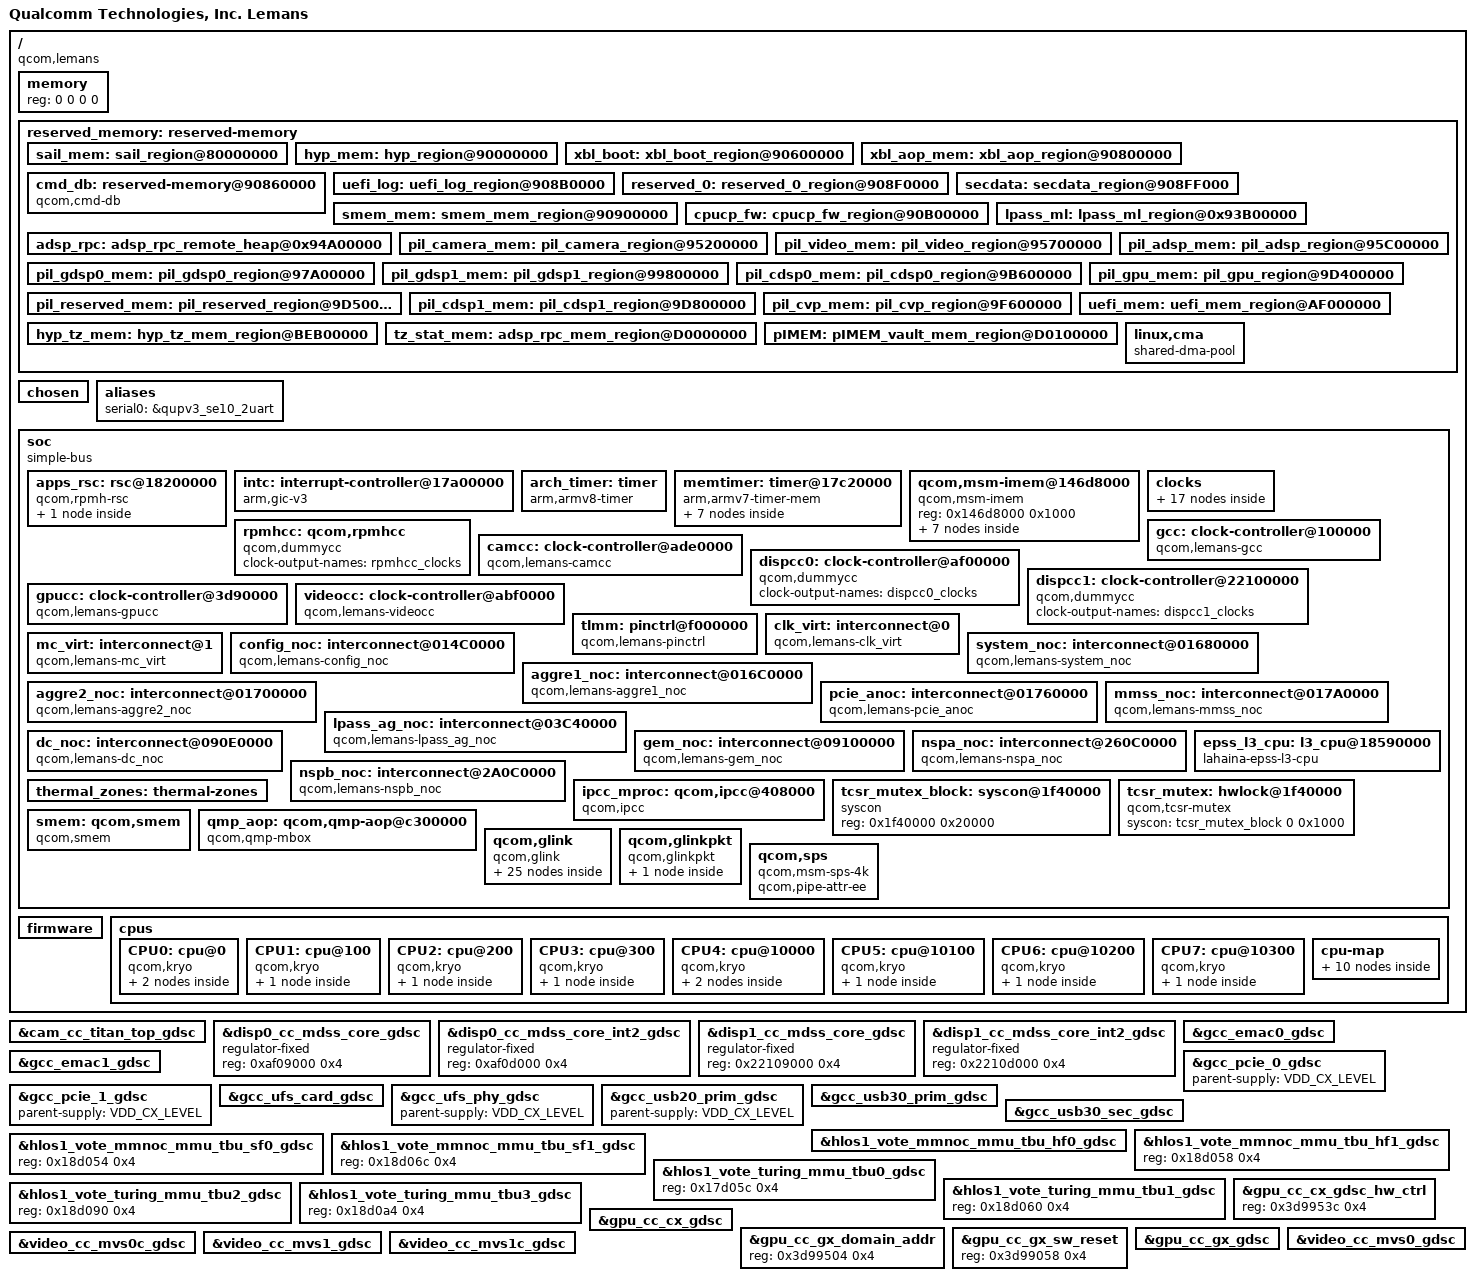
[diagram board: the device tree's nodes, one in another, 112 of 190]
#include <dt-bindings/clock/qcom,rpmh.h>
#include <dt-bindings/clock/qcom,camcc-lemans.h>
#include <dt-bindings/clock/qcom,dispcc-lemans.h>
#include <dt-bindings/clock/qcom,gcc-lemans.h>
#include <dt-bindings/clock/qcom,gpucc-lemans.h>
#include <dt-bindings/clock/qcom,videocc-lemans.h>
#include <dt-bindings/interconnect/qcom,epss-l3.h>
#include <dt-bindings/interconnect/qcom,lemans.h>
#include <dt-bindings/interrupt-controller/arm-gic.h>
#include <dt-bindings/soc/qcom,rpmh-rsc.h>
#include <dt-bindings/soc/qcom,ipcc.h>

/ {
	model = "Qualcomm Technologies, Inc. Lemans";
	compatible = "qcom,lemans";
	qcom,msm-id = <532 0x10000>, <534 0x10000>;
	interrupt-parent = <&intc>;

	#address-cells = <2>;
	#size-cells = <2>;
	memory { device_type = "memory"; reg = <0 0 0 0>; };

	reserved_memory: reserved-memory { };

	chosen: chosen { };

	aliases {
		serial0 = &qupv3_se10_2uart;
	 };

	soc: soc { };

	firmware: firmware { };

	cpus {
		#address-cells = <2>;
		#size-cells = <0>;

		CPU0: cpu@0 {
			device_type = "cpu";
			compatible = "qcom,kryo";
			reg = <0x0 0x0>;
			enable-method = "spin-table";
			cpu-release-addr = <0x0 0xC0000000>;
			cache-size = <0x20000>;
			next-level-cache = <&L2_0>;
			L2_0: l2-cache {
			      compatible = "arm,arch-cache";
			      cache-level = <2>;
			      cache-size = <0x80000>;
			      next-level-cache = <&L3_0>;

				L3_0: l3-cache {
				      compatible = "arm,arch-cache";
				      cache-level = <3>;
				      cache-size = <0x200000>;
				};
			};
		};

		CPU1: cpu@100 {
			device_type = "cpu";
			compatible = "qcom,kryo";
			reg = <0x0 0x100>;
			enable-method = "spin-table";
			cpu-release-addr = <0x0 0xC0000000>;
			cache-size = <0x20000>;
			next-level-cache = <&L2_1>;
			L2_1: l2-cache {
			      compatible = "arm,arch-cache";
			      cache-level = <2>;
			      cache-size = <0x80000>;
			      next-level-cache = <&L3_0>;
			};
		};

		CPU2: cpu@200 {
			device_type = "cpu";
			compatible = "qcom,kryo";
			reg = <0x0 0x200>;
			enable-method = "spin-table";
			cpu-release-addr = <0x0 0xC0000000>;
			cache-size = <0x20000>;
			next-level-cache = <&L2_2>;
			L2_2: l2-cache {
			      compatible = "arm,arch-cache";
			      cache-level = <2>;
			      cache-size = <0x80000>;
			      next-level-cache = <&L3_0>;
			};
		};

		CPU3: cpu@300 {
			device_type = "cpu";
			compatible = "qcom,kryo";
			reg = <0x0 0x300>;
			enable-method = "spin-table";
			cpu-release-addr = <0x0 0xC0000000>;
			cache-size = <0x20000>;
			next-level-cache = <&L2_3>;
			L2_3: l2-cache {
			      compatible = "arm,arch-cache";
			      cache-level = <2>;
			      cache-size = <0x80000>;
			      next-level-cache = <&L3_0>;
			};
		};

		CPU4: cpu@10000 {
			device_type = "cpu";
			compatible = "qcom,kryo";
			reg = <0x0 0x10000>;
			enable-method = "spin-table";
			cache-size = <0x20000>;
			cpu-release-addr = <0x0 0xC0000000>;
			next-level-cache = <&L2_4>;
			L2_4: l2-cache {
			      compatible = "arm,arch-cache";
			      cache-level = <2>;
			      cache-size = <0x80000>;
			      next-level-cache = <&L3_1>;
				L3_1: l3-cache {
				      compatible = "arm,arch-cache";
				      cache-level = <3>;
				      cache-size = <0x200000>;
				};

			};
		};

		CPU5: cpu@10100 {
			device_type = "cpu";
			compatible = "qcom,kryo";
			reg = <0x0 0x10100>;
			enable-method = "spin-table";
			cpu-release-addr = <0x0 0xC0000000>;
			cache-size = <0x20000>;
			next-level-cache = <&L2_5>;
			L2_5: l2-cache {
			      compatible = "arm,arch-cache";
			      cache-level = <2>;
			      cache-size = <0x80000>;
			      next-level-cache = <&L3_1>;
			};
		};

		CPU6: cpu@10200 {
			device_type = "cpu";
			compatible = "qcom,kryo";
			reg = <0x0 0x10200>;
			enable-method = "spin-table";
			cpu-release-addr = <0x0 0xC0000000>;
			cache-size = <0x20000>;
			next-level-cache = <&L2_6>;
			L2_6: l2-cache {
			      compatible = "arm,arch-cache";
			      cache-level = <2>;
			      cache-size = <0x80000>;
			      next-level-cache = <&L3_1>;
			};
		};

		CPU7: cpu@10300 {
			device_type = "cpu";
			compatible = "qcom,kryo";
			reg = <0x0 0x10300>;
			enable-method = "spin-table";
			cpu-release-addr = <0x0 0xC0000000>;
			cache-size = <0x20000>;
			next-level-cache = <&L2_7>;
			L2_7: l2-cache {
			      compatible = "arm,arch-cache";
			      cache-level = <2>;
			      cache-size = <0x80000>;
			      next-level-cache = <&L3_1>;
			};
		};

		cpu-map {
			cluster0 {
				core0 {
					cpu = <&CPU0>;
				};

				core1 {
					cpu = <&CPU1>;
				};

				core2 {
					cpu = <&CPU2>;
				};

				core3 {
					cpu = <&CPU3>;
				};
			};

			cluster1 {
				core0 {
					cpu = <&CPU4>;
				};

				core1 {
					cpu = <&CPU5>;
				};

				core2 {
					cpu = <&CPU6>;
				};

				core3 {
					cpu = <&CPU7>;
				};
			};
		};
	};
};

&reserved_memory {
	#address-cells = <2>;
	#size-cells = <2>;
	ranges;

	sail_mem: sail_region@80000000 {
		no-map;
		reg = <0x0 0x80000000 0x0 0x10000000>;
	};

	hyp_mem: hyp_region@90000000 {
		no-map;
		reg = <0x0 0x90000000 0x0 0x600000>;
	};

	xbl_boot: xbl_boot_region@90600000 {
		no-map;
		reg = <0x0 0x90600000 0x0 0x200000>;
	};

	xbl_aop_mem: xbl_aop_region@90800000 {
		no-map;
		reg = <0x0 0x90800000 0x0 0x60000>;
	};

	cmd_db: reserved-memory@90860000 {
		compatible = "qcom,cmd-db";
		no-map;
		reg = <0x0 0x90860000 0x0 0x20000>;
	};

	uefi_log: uefi_log_region@908B0000 {
		no-map;
		reg = <0x0 0x908B0000 0x0 0x10000>;
	};

	reserved_0: reserved_0_region@908F0000 {
		no-map;
		reg = <0x0 0x908F0000 0x0 0xF000>;
	};

	secdata: secdata_region@908FF000 {
		no-map;
		reg = <0x0 0x908FF000 0x0 0x1000>;
	};

	smem_mem: smem_mem_region@90900000 {
		no-map;
		reg = <0x0 0x90900000 0x0 0x200000>;
	};

	cpucp_fw: cpucp_fw_region@90B00000 {
		no-map;
		reg = <0x0 0x90B00000 0x0 0x100000>;
	};

	lpass_ml: lpass_ml_region@0x93B00000 {
		no-map;
		reg = <0x0 0x93B00000 0x0 0xF00000>;
	};

	adsp_rpc: adsp_rpc_remote_heap@0x94A00000 {
		no-map;
		reg = <0x0 0x94A00000 0x0 0x800000>;
	};

	pil_camera_mem: pil_camera_region@95200000 {
		no-map;
		reg = <0x0 0x95200000 0x0 0x500000>;
	};

	pil_video_mem: pil_video_region@95700000 {
		no-map;
		reg = <0x0 0x95700000 0x0 0x500000>;
	};

	pil_adsp_mem: pil_adsp_region@95C00000 {
		no-map;
		reg = <0x0 0x95C00000 0x0 0x1E00000>;
	};

	pil_gdsp0_mem: pil_gdsp0_region@97A00000 {
		no-map;
		reg = <0x0 0x97A00000 0x0 0x1e00000>;
	};

	pil_gdsp1_mem: pil_gdsp1_region@99800000 {
		no-map;
		reg = <0x0 0x99800000 0x0 0x1e00000>;
	};

	pil_cdsp0_mem: pil_cdsp0_region@9B600000 {
		no-map;
		reg = <0x0 0x9B600000 0x0 0x1e00000>;
	};

	pil_gpu_mem: pil_gpu_region@9D400000 {
		no-map;
		reg = <0x0 0x9D400000 0x0 0x2000>;
	};

	pil_reserved_mem: pil_reserved_region@9D500000 {
		no-map;
		reg = <0x0 0x9D500000 0x0 0x300000>;
	};

	pil_cdsp1_mem: pil_cdsp1_region@9D800000 {
		no-map;
		reg = <0x0 0x9D800000 0x0 0x1E00000>;
	};

	pil_cvp_mem: pil_cvp_region@9F600000 {
		no-map;
		reg = <0x0 0x9F600000 0x0 0x700000>;
	};

	uefi_mem: uefi_mem_region@AF000000 {
		no-map;
		reg = <0x0 0xAF000000 0x0 0x1000000>;
	};

	hyp_tz_mem: hyp_tz_mem_region@BEB00000 {
		no-map;
		reg = <0x0 0xBEB00000 0x0 0x11500000>;
	};

	tz_stat_mem: adsp_rpc_mem_region@D0000000 {
		no-map;
		reg = <0x0 0xD0000000 0x0 0x100000>;
	};

	pIMEM: pIMEM_vault_mem_region@D0100000 {
		no-map;
		reg = <0x0 0xD0100000 0x0 0x5000000>;
	};

	  /* global autoconfigured region for contiguous allocations */
	linux,cma {
		compatible = "shared-dma-pool";
		alloc-ranges = <0x0 0x00000000 0x0 0xdfffffff>;
		reusable;
		alignment = <0x0 0x400000>;
		size = <0x0 0x2000000>;
		linux,cma-default;
	};
};

&soc {
	#address-cells = <1>;
	#size-cells = <1>;
	ranges = <0 0 0 0xffffffff>;
	compatible = "simple-bus";

	apps_rsc: rsc@18200000 {
		label = "apps_rsc";
		compatible = "qcom,rpmh-rsc";
		reg = <0x18200000 0x10000>,
		      <0x18210000 0x10000>,
		      <0x18220000 0x10000>;
		reg-names = "drv-0", "drv-1", "drv-2";
		interrupts = <GIC_SPI 3 IRQ_TYPE_LEVEL_HIGH>,
			     <GIC_SPI 4 IRQ_TYPE_LEVEL_HIGH>,
			     <GIC_SPI 5 IRQ_TYPE_LEVEL_HIGH>;
		qcom,tcs-offset = <0xd00>;
		qcom,drv-id = <2>;
		qcom,tcs-config = <ACTIVE_TCS  2>,
				  <SLEEP_TCS   3>,
				  <WAKE_TCS    3>,
				  <CONTROL_TCS 0>;

		apps_bcm_voter: bcm_voter {
			compatible = "qcom,bcm-voter";
		};
	};

	intc: interrupt-controller@17a00000 {
		compatible = "arm,gic-v3";
		#interrupt-cells = <3>;
		interrupt-controller;
		#redistributor-regions = <1>;
		redistributor-stride = <0x0 0x20000>;
		reg = <0x17a00000 0x10000>,     /* GICD */
		      <0x17a60000 0x100000>;    /* GICR * 8 */
		interrupts = <GIC_PPI 9 IRQ_TYPE_LEVEL_HIGH>;
	};

	arch_timer: timer {
		compatible = "arm,armv8-timer";
		interrupts = <GIC_PPI 13 (GIC_CPU_MASK_SIMPLE(8) | IRQ_TYPE_LEVEL_LOW)>,
			     <GIC_PPI 14 (GIC_CPU_MASK_SIMPLE(8) | IRQ_TYPE_LEVEL_LOW)>,
			     <GIC_PPI 11 (GIC_CPU_MASK_SIMPLE(8) | IRQ_TYPE_LEVEL_LOW)>,
			     <GIC_PPI 12 (GIC_CPU_MASK_SIMPLE(8) | IRQ_TYPE_LEVEL_LOW)>;
		clock-frequency = <19200000>;
	};

	memtimer: timer@17c20000 {
		#address-cells = <1>;
		#size-cells = <1>;
		ranges;
		compatible = "arm,armv7-timer-mem";
		reg = <0x17c20000 0x1000>;
		clock-frequency = <19200000>;

		frame@17c21000 {
			frame-number = <0>;
			interrupts = <GIC_SPI 8 IRQ_TYPE_LEVEL_HIGH>,
				     <GIC_SPI 6 IRQ_TYPE_LEVEL_HIGH>;
			reg = <0x17c21000 0x1000>,
			      <0x17c22000 0x1000>;
		};

		frame@17c23000 {
			frame-number = <1>;
			interrupts = <GIC_SPI 9 IRQ_TYPE_LEVEL_HIGH>;
			reg = <0x17c23000 0x1000>;
			status = "disabled";
		};

		frame@17c25000 {
			frame-number = <2>;
			interrupts = <GIC_SPI 10 IRQ_TYPE_LEVEL_HIGH>;
			reg = <0x17c25000 0x1000>;
			status = "disabled";
		};

		frame@17c27000 {
			frame-number = <3>;
			interrupts = <GIC_SPI 11 IRQ_TYPE_LEVEL_HIGH>;
			reg = <0x17c27000 0x1000>;
			status = "disabled";
		};

		frame@17c29000 {
			frame-number = <4>;
			interrupts = <GIC_SPI 12 IRQ_TYPE_LEVEL_HIGH>;
			reg = <0x17c29000 0x1000>;
			status = "disabled";
		};

		frame@17c2b000 {
			frame-number = <5>;
			interrupts = <GIC_SPI 13 IRQ_TYPE_LEVEL_HIGH>;
			reg = <0x17c2b000 0x1000>;
			status = "disabled";
		};

		frame@17c2d000 {
			frame-number = <6>;
			interrupts = <GIC_SPI 14 IRQ_TYPE_LEVEL_HIGH>;
			reg = <0x17c2d000 0x1000>;
			status = "disabled";
		};
	};

	qcom,msm-imem@146d8000 {
		compatible = "qcom,msm-imem";
		reg = <0x146d8000 0x1000>;
		ranges = <0x0 0x146d8000 0x1000>;
		#address-cells = <1>;
		#size-cells = <1>;

		mem_dump_table@10 {
			compatible = "qcom,msm-imem-mem_dump_table";
			reg = <0x10 0x8>;
		};

		restart_reason@65c {
			compatible = "qcom,msm-imem-restart_reason";
			reg = <0x65c 0x4>;
		};

		dload_type@1c {
			compatible = "qcom,msm-imem-dload-type";
			reg = <0x1c 0x4>;
		};

		boot_stats@6b0 {
			compatible = "qcom,msm-imem-boot_stats";
			reg = <0x6b0 0x20>;
		};

		kaslr_offset@6d0 {
			compatible = "qcom,msm-imem-kaslr_offset";
			reg = <0x6d0 0xc>;
		};

		pil@94c {
			compatible = "qcom,msm-imem-pil";
			reg = <0x94c 0xc8>;
		};

		diag_dload@c8 {
			compatible = "qcom,msm-imem-diag-dload";
			reg = <0xc8 0xc8>;
		};
	};

	clocks {
		xo_board: xo_board {
			compatible = "fixed-clock";
			clock-frequency = <38400000>;
			clock-output-names = "xo_board";
			#clock-cells = <0>;
		};

		bi_tcxo: bi_tcxo {
			compatible = "fixed-factor-clock";
			clock-mult = <1>;
			clock-div = <2>;
			clocks = <&xo_board>;
			clock-output-names = "bi_tcxo";
			#clock-cells = <0>;
		};

		bi_tcxo_ao: bi_tcxo_ao {
			compatible = "fixed-factor-clock";
			clock-mult = <1>;
			clock-div = <2>;
			clocks = <&xo_board>;
			clock-output-names = "bi_tcxo_ao";
			#clock-cells = <0>;
		};

		sleep_clk: sleep_clk {
			compatible = "fixed-clock";
			clock-frequency = <32000>;
			clock-output-names = "sleep_clk";
			#clock-cells = <0>;
		};

		pcie_0_pipe_clk: pcie_0_pipe_clk {
			compatible = "fixed-clock";
			clock-frequency = <1000>;
			clock-output-names = "pcie_0_pipe_clk";
			#clock-cells = <0>;
		};

		pcie_1_pipe_clk: pcie_1_pipe_clk {
			compatible = "fixed-clock";
			clock-frequency = <1000>;
			clock-output-names = "pcie_1_pipe_clk";
			#clock-cells = <0>;
		};

		pcie_phy_aux_clk: pcie_phy_aux_clk {
			compatible = "fixed-clock";
			clock-frequency = <1000>;
			clock-output-names = "pcie_phy_aux_clk";
			#clock-cells = <0>;
		};

		rxc0_ref_clk: rxc0_ref_clk {
			compatible = "fixed-clock";
			clock-frequency = <1000>;
			clock-output-names = "rxc0_ref_clk";
			#clock-cells = <0>;
		};

		rxc1_ref_clk: rxc1_ref_clk {
			compatible = "fixed-clock";
			clock-frequency = <1000>;
			clock-output-names = "rxc0_ref_clk";
			#clock-cells = <0>;
		};

		ufs_card_rx_symbol_0_clk: ufs_card_rx_symbol_0_clk {
			compatible = "fixed-clock";
			clock-frequency = <1000>;
			clock-output-names = "ufs_card_rx_symbol_0_clk";
			#clock-cells = <0>;
		};

		ufs_card_rx_symbol_1_clk: ufs_card_rx_symbol_1_clk {
			compatible = "fixed-clock";
			clock-frequency = <1000>;
			clock-output-names = "ufs_card_rx_symbol_1_clk";
			#clock-cells = <0>;
		};

		ufs_card_tx_symbol_0_clk: ufs_card_tx_symbol_0_clk {
			compatible = "fixed-clock";
			clock-frequency = <1000>;
			clock-output-names = "ufs_card_tx_symbol_0_clk";
			#clock-cells = <0>;
		};

		ufs_phy_rx_symbol_0_clk: ufs_phy_rx_symbol_0_clk {
			compatible = "fixed-clock";
			clock-frequency = <1000>;
			clock-output-names = "ufs_phy_rx_symbol_0_clk";
			#clock-cells = <0>;
		};

		ufs_phy_rx_symbol_1_clk: ufs_phy_rx_symbol_1_clk {
			compatible = "fixed-clock";
			clock-frequency = <1000>;
			clock-output-names = "ufs_phy_rx_symbol_1_clk";
			#clock-cells = <0>;
		};

		ufs_phy_tx_symbol_0_clk: ufs_phy_tx_symbol_0_clk {
			compatible = "fixed-clock";
			clock-frequency = <1000>;
			clock-output-names = "ufs_phy_tx_symbol_0_clk";
			#clock-cells = <0>;
		};

		usb3_phy_wrapper_gcc_usb30_prim_pipe_clk: usb3_phy_wrapper_gcc_usb30_prim_pipe_clk {
			compatible = "fixed-clock";
			clock-frequency = <1000>;
			clock-output-names = "usb3_phy_wrapper_gcc_usb30_prim_pipe_clk";
			#clock-cells = <0>;
		};

		usb3_phy_wrapper_gcc_usb30_sec_pipe_clk: usb3_phy_wrapper_gcc_usb30_sec_pipe_clk {
			compatible = "fixed-clock";
			clock-frequency = <1000>;
			clock-output-names = "usb3_phy_wrapper_gcc_usb30_sec_pipe_clk";
			#clock-cells = <0>;
		};
	};

	rpmhcc: qcom,rpmhcc {
		compatible = "qcom,dummycc";
		clock-output-names = "rpmhcc_clocks";
		#clock-cells = <1>;
		#reset-cells = <1>;
	};

	gcc: clock-controller@100000 {
		compatible = "qcom,lemans-gcc", "syscon";
		reg = <0x100000 0xc7018>;
		reg-name = "cc_base";
		vdd_cx-supply = <&VDD_CX_LEVEL>;
		clocks = <&rpmhcc RPMH_CXO_CLK>, <&pcie_0_pipe_clk>, <&pcie_1_pipe_clk>,
			 <&pcie_phy_aux_clk>, <&rxc0_ref_clk>, <&rxc1_ref_clk>, <&sleep_clk>,
			 <&ufs_card_rx_symbol_0_clk>, <&ufs_card_rx_symbol_1_clk>,
			 <&ufs_card_tx_symbol_0_clk>, <&ufs_phy_rx_symbol_0_clk>,
			 <&ufs_phy_rx_symbol_1_clk>, <&ufs_phy_tx_symbol_0_clk>,
			 <&usb3_phy_wrapper_gcc_usb30_prim_pipe_clk>,
			 <&usb3_phy_wrapper_gcc_usb30_sec_pipe_clk>;
		clock-names = "bi_tcxo", "pcie_0_pipe_clk", "pcie_1_pipe_clk",
			      "pcie_phy_aux_clk", "rxc0_ref_clk", "rxc1_ref_clk", "sleep_clk",
			      "ufs_card_rx_symbol_0_clk", "ufs_card_rx_symbol_1_clk",
			      "ufs_card_tx_symbol_0_clk", "ufs_phy_rx_symbol_0_clk",
			      "ufs_phy_rx_symbol_1_clk", "ufs_phy_tx_symbol_0_clk",
			      "usb3_phy_wrapper_gcc_usb30_prim_pipe_clk",
			      "usb3_phy_wrapper_gcc_usb30_sec_pipe_clk";
		#clock-cells = <1>;
		#reset-cells = <1>;
	};

	camcc: clock-controller@ade0000 {
		compatible = "qcom,lemans-camcc", "syscon";
		reg = <0xade0000 0x20000>;
		reg-name = "cc_base";
		vdd_mm-supply = <&VDD_MM_LEVEL>;
		vdd_mxa-supply = <&VDD_MXA_LEVEL>;
		vdd_mxc-supply = <&VDD_MXC_LEVEL>;
		clocks = <&rpmhcc RPMH_CXO_CLK>, <&gcc GCC_CAMERA_AHB_CLK>, <&sleep_clk>;
		clock-names = "bi_tcxo", "iface", "sleep_clk";
		#clock-cells = <1>;
		#reset-cells = <1>;
	};

	dispcc0: clock-controller@af00000 {
		compatible = "qcom,dummycc";
		clock-output-names = "dispcc0_clocks";
		#clock-cells = <1>;
		#reset-cells = <1>;
	};

	dispcc1: clock-controller@22100000 {
		compatible = "qcom,dummycc";
		clock-output-names = "dispcc1_clocks";
		#clock-cells = <1>;
		#reset-cells = <1>;
	};

	gpucc: clock-controller@3d90000 {
		compatible = "qcom,lemans-gpucc", "syscon";
		reg = <0x3d90000 0xa000>;
		reg-name = "cc_base";
		vdd_cx-supply = <&VDD_CX_LEVEL>;
		vdd_mxa-supply = <&VDD_MXA_LEVEL>;
		clocks = <&rpmhcc RPMH_CXO_CLK>, <&gcc GCC_GPU_CFG_AHB_CLK>,
			 <&gcc GCC_GPU_GPLL0_CLK_SRC>, <&gcc GCC_GPU_GPLL0_DIV_CLK_SRC>;
		clock-names = "bi_tcxo", "iface", "gpll0_out_main", "gpll0_out_main_div";
		#clock-cells = <1>;
		#reset-cells = <1>;
	};

	videocc: clock-controller@abf0000 {
		compatible = "qcom,lemans-videocc", "syscon";
		reg = <0xabf0000 0x10000>;
		reg-name = "cc_base";
		vdd_mm-supply = <&VDD_MM_LEVEL>;
		vdd_mx-supply = <&VDD_MXA_LEVEL>;
		clocks = <&rpmhcc RPMH_CXO_CLK>, <&gcc GCC_VIDEO_AHB_CLK>, <&sleep_clk>;
		clock-names = "bi_tcxo", "iface", "sleep_clk";
		#clock-cells = <1>;
		#reset-cells = <1>;
	};

	tlmm: pinctrl@f000000 {
		compatible = "qcom,lemans-pinctrl";
		reg = <0xf000000 0x1000000>;
		interrupts = <GIC_SPI 208 IRQ_TYPE_LEVEL_HIGH>;
		gpio-controller;
		#gpio-cells = <2>;
		interrupt-controller;
		#interrupt-cells = <2>;
	};

	clk_virt: interconnect@0 {
		compatible = "qcom,lemans-clk_virt";
		#interconnect-cells = <1>;
		qcom,bcm-voter-names = "hlos";
		qcom,bcm-voters = <&apps_bcm_voter>;
	};

	mc_virt: interconnect@1 {
		compatible = "qcom,lemans-mc_virt";
		#interconnect-cells = <1>;
		qcom,bcm-voter-names = "hlos";
		qcom,bcm-voters = <&apps_bcm_voter>;
	};

	config_noc: interconnect@014C0000 {
		compatible = "qcom,lemans-config_noc";
		reg = <0x014C0000 0x13080>;
		#interconnect-cells = <1>;
		qcom,bcm-voter-names = "hlos";
		qcom,bcm-voters = <&apps_bcm_voter>;
	};

	system_noc: interconnect@01680000 {
		compatible = "qcom,lemans-system_noc";
		reg = <0x01680000 0x15080>;
		#interconnect-cells = <1>;
		qcom,bcm-voter-names = "hlos";
		qcom,bcm-voters = <&apps_bcm_voter>;
	};

	aggre1_noc:interconnect@016C0000 {
		compatible = "qcom,lemans-aggre1_noc";
		reg = <0x016C0000 0x18080>;
		#interconnect-cells = <1>;
		qcom,bcm-voter-names = "hlos";
		qcom,bcm-voters = <&apps_bcm_voter>;
	};

	aggre2_noc: interconnect@01700000 {
		compatible = "qcom,lemans-aggre2_noc";
		reg = <0x01700000 0x1B080>;
		#interconnect-cells = <1>;
		qcom,bcm-voter-names = "hlos";
		qcom,bcm-voters = <&apps_bcm_voter>;
	};

	pcie_anoc: interconnect@01760000 {
		compatible = "qcom,lemans-pcie_anoc";
		reg = <0x01760000 0xC080>;
		#interconnect-cells = <1>;
		qcom,bcm-voter-names = "hlos";
		qcom,bcm-voters = <&apps_bcm_voter>;
	};

	mmss_noc: interconnect@017A0000 {
		compatible = "qcom,lemans-mmss_noc";
		reg = <0x017A0000 0x40000>;
		#interconnect-cells = <1>;
		qcom,bcm-voter-names = "hlos";
		qcom,bcm-voters = <&apps_bcm_voter>;
	};

	lpass_ag_noc: interconnect@03C40000 {
		compatible = "qcom,lemans-lpass_ag_noc";
		reg = <0x3C40000 0x17200>;
		#interconnect-cells = <1>;
		qcom,bcm-voter-names = "hlos";
		qcom,bcm-voters = <&apps_bcm_voter>;
	};

	dc_noc: interconnect@090E0000 {
		compatible = "qcom,lemans-dc_noc";
		reg = <0x090E0000 0x5080>;
		#interconnect-cells = <1>;
		qcom,bcm-voter-names = "hlos";
		qcom,bcm-voters = <&apps_bcm_voter>;
	};

	gem_noc: interconnect@09100000 {
		compatible = "qcom,lemans-gem_noc";
		reg = <0x09100000 0xF6080>;
		#interconnect-cells = <1>;
		qcom,bcm-voter-names = "hlos";
		qcom,bcm-voters = <&apps_bcm_voter>;
	};

	nspa_noc: interconnect@260C0000 {
		compatible = "qcom,lemans-nspa_noc";
		reg = <0x260C0000 0x16080>;
		#interconnect-cells = <1>;
		qcom,bcm-voter-names = "hlos";
		qcom,bcm-voters = <&apps_bcm_voter>;
	};

	nspb_noc: interconnect@2A0C0000 {
		compatible = "qcom,lemans-nspb_noc";
		reg = <0x2A0C0000 0x16080>;
		#interconnect-cells = <1>;
		qcom,bcm-voter-names = "hlos";
		qcom,bcm-voters = <&apps_bcm_voter>;
	};

	epss_l3_cpu: l3_cpu@18590000 {
		compatible = "lahaina-epss-l3-cpu";
		#interconnect-cells = <1>;
	};

	thermal_zones: thermal-zones {
	};

	ipcc_mproc: qcom,ipcc@408000 {
		compatible = "qcom,ipcc";
		reg = <0x408000 0x1000>;
		interrupts = <GIC_SPI 229 IRQ_TYPE_LEVEL_HIGH>;
		interrupt-controller;
		#interrupt-cells = <3>;
		#mbox-cells = <2>;
	};

	tcsr_mutex_block: syscon@1f40000 {
		compatible = "syscon";
		reg = <0x1f40000 0x20000>;
	};

	tcsr_mutex: hwlock@1f40000 {
		compatible = "qcom,tcsr-mutex";
		syscon = <&tcsr_mutex_block 0 0x1000>;
		#hwlock-cells = <1>;
	};

	smem: qcom,smem {
		compatible = "qcom,smem";
		memory-region = <&smem_mem>;
		hwlocks = <&tcsr_mutex 3>;
	};

	qmp_aop: qcom,qmp-aop@c300000 {
		compatible = "qcom,qmp-mbox";
		mboxes = <&ipcc_mproc IPCC_CLIENT_AOP
			  IPCC_MPROC_SIGNAL_GLINK_QMP>;
		mbox-names = "aop_qmp";
		interrupt-parent = <&ipcc_mproc>;
		interrupts = <IPCC_CLIENT_AOP
			      IPCC_MPROC_SIGNAL_GLINK_QMP
			      IRQ_TYPE_EDGE_RISING>;
		reg = <0xc300000 0x400>;
		reg-names = "msgram";

		label = "aop";
		qcom,early-boot;
		priority = <0>;
		mbox-desc-offset = <0x0>;
		#mbox-cells = <1>;
	};

	qcom,glink {
		compatible = "qcom,glink";
		#address-cells = <1>;
		#size-cells = <1>;
		ranges;

		glink_adsp: adsp {
			qcom,remote-pid = <2>;
			transport = "smem";
			mboxes = <&ipcc_mproc IPCC_CLIENT_LPASS
				  IPCC_MPROC_SIGNAL_GLINK_QMP>;
			mbox-names = "adsp_smem";
			interrupt-parent = <&ipcc_mproc>;
			interrupts = <IPCC_CLIENT_LPASS
				      IPCC_MPROC_SIGNAL_GLINK_QMP
				      IRQ_TYPE_EDGE_RISING>;

			label = "adsp";
			qcom,glink-label = "lpass";
			cpu-affinity = <1 2>;

			qcom,adsp_qrtr {
				qcom,glink-channels = "IPCRTR";
				qcom,intents = <0x800  5
						0x2000 3
						0x4400 2>;
			};

			qcom,apr_tal_rpmsg {
				qcom,glink-channels = "apr_audio_svc";
				qcom,intents = <0x200 20>;
			};

			qcom,msm_fastrpc_rpmsg {
				compatible = "qcom,msm-fastrpc-rpmsg";
				qcom,glink-channels = "fastrpcglink-apps-dsp";
				qcom,intents = <0x64 64>;
			};

			qcom,adsp_glink_ssr {
				qcom,glink-channels = "glink_ssr";
				qcom,notify-edges = <&glink_gpdsp0>,
						    <&glink_gpdsp1>;
			};
		};

		glink_cdsp0: cdsp0 {
			qcom,remote-pid = <5>;
			transport = "smem";
			mboxes = <&ipcc_mproc IPCC_CLIENT_CDSP
				  IPCC_MPROC_SIGNAL_GLINK_QMP>;
			mbox-names = "cdsp0_smem";
			interrupt-parent = <&ipcc_mproc>;
			interrupts = <IPCC_CLIENT_CDSP
				      IPCC_MPROC_SIGNAL_GLINK_QMP
				      IRQ_TYPE_EDGE_RISING>;

			label = "cdsp0";
			qcom,glink-label = "cdsp0";

			qcom,cdsp0_qrtr {
				qcom,glink-channels = "IPCRTR";
				qcom,intents = <0x800  5
						0x2000 3
						0x4400 2>;
			};

			qcom,msm_fastrpc_rpmsg {
				compatible = "qcom,msm-fastrpc-rpmsg";
				qcom,glink-channels = "fastrpcglink-apps-dsp";
				qcom,intents = <0x64 64>;
			};

			qcom,msm_cdsprm_rpmsg {
				compatible = "qcom,msm-cdsprm-rpmsg";
				qcom,glink-channels = "cdsprmglink-apps-dsp";
				qcom,intents = <0x20 12>;

				msm_cdsp_rm: qcom,msm_cdsp_rm {
					compatible = "qcom,msm-cdsp-rm";
					qcom,qos-latency-us = <44>;
					qcom,qos-maxhold-ms = <20>;
					qcom,compute-cx-limit-en;
					qcom,compute-priority-mode = <2>;
					#cooling-cells = <2>;
				};
			};

			qcom,cdsp0_glink_ssr {
				qcom,glink-channels = "glink_ssr";
				qcom,notify-edges = <&glink_adsp>,
						    <&glink_cdsp1>;
			};
		};

		glink_cdsp1: cdsp1 {
			qcom,remote-pid = <12>;
			transport = "smem";
			mboxes = <&ipcc_mproc IPCC_CLIENT_NSP1
				  IPCC_MPROC_SIGNAL_GLINK_QMP>;
			mbox-names = "cdsp1_smem";
			interrupt-parent = <&ipcc_mproc>;
			interrupts = <IPCC_CLIENT_NSP1
				      IPCC_MPROC_SIGNAL_GLINK_QMP
				      IRQ_TYPE_EDGE_RISING>;

			label = "cdsp1";
			qcom,glink-label = "cdsp1";

			qcom,cdsp1_qrtr {
				qcom,glink-channels = "IPCRTR";
				qcom,intents = <0x800  5
						0x2000 3
						0x4400 2>;
			};

			qcom,msm_fastrpc_rpmsg {
				compatible = "qcom,msm-fastrpc-rpmsg";
				qcom,glink-channels = "fastrpcglink-apps-dsp";
				qcom,intents = <0x64 64>;
			};

			qcom,cdsp1_glink_ssr {
				qcom,glink-channels = "glink_ssr";
				qcom,notify-edges = <&glink_adsp>,
						    <&glink_cdsp0>;
			};
		};

		glink_gpdsp0: gpdsp0 {
			qcom,remote-pid = <17>;
			transport = "smem";
			mboxes = <&ipcc_mproc IPCC_CLIENT_GPDSP0
				  IPCC_MPROC_SIGNAL_GLINK_QMP>;
			mbox-names = "gpdsp0_smem";
			interrupt-parent = <&ipcc_mproc>;
			interrupts = <IPCC_CLIENT_GPDSP0
				      IPCC_MPROC_SIGNAL_GLINK_QMP
				      IRQ_TYPE_EDGE_RISING>;

			label = "gpdsp0";
			qcom,glink-label = "gpdsp0";

			qcom,gpdsp0_qrtr {
				qcom,glink-channels = "IPCRTR";
				qcom,intents = <0x800  5
						0x2000 3
						0x4400 2>;
			};

			qcom,apr_tal_rpmsg {
				qcom,glink-channels = "apr_audio_svc";
				qcom,intents = <0x200 20>;
			};

			qcom,msm_fastrpc_rpmsg {
				compatible = "qcom,msm-fastrpc-rpmsg";
				qcom,glink-channels = "fastrpcglink-apps-dsp";
				qcom,intents = <0x64 64>;
			};

			qcom,gpdsp0_glink_ssr {
				qcom,glink-channels = "glink_ssr";
				qcom,notify-edges = <&glink_adsp>,
						    <&glink_cdsp0>,
						    <&glink_cdsp1>,
						    <&glink_gpdsp1>;
			};
		};

		glink_gpdsp1: gpdsp1 {
			qcom,remote-pid = <18>;
			transport = "smem";
			mboxes = <&ipcc_mproc IPCC_CLIENT_GPDSP1
				  IPCC_MPROC_SIGNAL_GLINK_QMP>;
			mbox-names = "gpdsp1_smem";
			interrupt-parent = <&ipcc_mproc>;
			interrupts = <IPCC_CLIENT_GPDSP1
				      IPCC_MPROC_SIGNAL_GLINK_QMP
				      IRQ_TYPE_EDGE_RISING>;

			label = "gpdsp1";
			qcom,glink-label = "gpdsp1";

			qcom,gpdsp1_qrtr {
				qcom,glink-channels = "IPCRTR";
				qcom,intents = <0x800  5
						0x2000 3
						0x4400 2>;
			};

			qcom,apr_tal_rpmsg {
				qcom,glink-channels = "apr_audio_svc";
				qcom,intents = <0x200 20>;
			};

			qcom,msm_fastrpc_rpmsg {
				compatible = "qcom,msm-fastrpc-rpmsg";
				qcom,glink-channels = "fastrpcglink-apps-dsp";
				qcom,intents = <0x64 64>;
			};

			qcom,gpdsp1_glink_ssr {
				qcom,glink-channels = "glink_ssr";
				qcom,notify-edges = <&glink_cdsp0>,
						    <&glink_cdsp1>,
						    <&glink_adsp>,
						    <&glink_gpdsp0>;
			};
		};
	};

	qcom,glinkpkt {
		compatible = "qcom,glinkpkt";

		qcom,glinkpkt-apr-apps2 {
			qcom,glinkpkt-edge = "adsp";
			qcom,glinkpkt-ch-name = "apr_apps2";
			qcom,glinkpkt-dev-name = "apr_apps2";
		};
	};

	qcom,sps {
		compatible = "qcom,msm-sps-4k";
		qcom,pipe-attr-ee;
	};
};

#include "lemans-gdsc.dtsi"
#include "lemans-pinctrl.dtsi"
#include "lemans-qupv3.dtsi"
#include "lemans-usb.dtsi"
#include "lemans-smp2p.dtsi"

&cam_cc_titan_top_gdsc {
	reg = <0xadf31bc 0x4>;
	clocks = <&gcc GCC_CAMERA_AHB_CLK>;
	clock-names = "ahb_clk";
	parent-supply = <&VDD_MM_MXC_VOTER_LEVEL>;
	status = "ok";
};

&disp0_cc_mdss_core_gdsc {
	compatible = "regulator-fixed";
	reg = <0xaf09000 0x4>;
	status = "ok";
};

&disp0_cc_mdss_core_int2_gdsc {
	compatible = "regulator-fixed";
	reg = <0xaf0d000 0x4>;
	status = "ok";
};

&disp1_cc_mdss_core_gdsc {
	compatible = "regulator-fixed";
	reg = <0x22109000 0x4>;
	status = "ok";
};

&disp1_cc_mdss_core_int2_gdsc {
	compatible = "regulator-fixed";
	reg = <0x2210d000 0x4>;
	status = "ok";
};

&gcc_emac0_gdsc {
	reg = <0x1b6004 0x4>;
	parent-supply = <&VDD_CX_LEVEL>;
	status = "ok";
};

&gcc_emac1_gdsc {
	reg = <0x1b4004 0x4>;
	parent-supply = <&VDD_CX_LEVEL>;
	status = "ok";
};

&gcc_pcie_0_gdsc {
	parent-supply = <&VDD_CX_LEVEL>;
	status = "ok";
};

&gcc_pcie_1_gdsc {
	parent-supply = <&VDD_CX_LEVEL>;
	status = "ok";
};

&gcc_ufs_card_gdsc {
	reg = <0x181004 0x4>;
	parent-supply = <&VDD_CX_LEVEL>;
	status = "ok";
};

&gcc_ufs_phy_gdsc {
	parent-supply = <&VDD_CX_LEVEL>;
	status = "ok";
};

&gcc_usb20_prim_gdsc {
	parent-supply = <&VDD_CX_LEVEL>;
	status = "ok";
};

&gcc_usb30_prim_gdsc {
	reg = <0x11b004 0x4>;
	parent-supply = <&VDD_CX_LEVEL>;
	status = "ok";
};

&gcc_usb30_sec_gdsc {
	reg = <0x12f004 0x4>;
	parent-supply = <&VDD_CX_LEVEL>;
	status = "ok";
};

&hlos1_vote_mmnoc_mmu_tbu_hf0_gdsc {
	reg = <0x18d050 0x4>;
	parent-supply = <&VDD_CX_LEVEL>;
	status = "ok";
};

&hlos1_vote_mmnoc_mmu_tbu_hf1_gdsc {
	reg = <0x18d058 0x4>;
	status = "ok";
};

&hlos1_vote_mmnoc_mmu_tbu_sf0_gdsc {
	reg = <0x18d054 0x4>;
	status = "ok";
};

&hlos1_vote_mmnoc_mmu_tbu_sf1_gdsc {
	reg = <0x18d06c 0x4>;
	status = "ok";
};

&hlos1_vote_turing_mmu_tbu0_gdsc {
	reg = <0x17d05c 0x4>;
	status = "ok";
};

&hlos1_vote_turing_mmu_tbu1_gdsc {
	reg = <0x18d060 0x4>;
	status = "ok";
};

&hlos1_vote_turing_mmu_tbu2_gdsc {
	reg = <0x18d090 0x4>;
	status = "ok";
};

&hlos1_vote_turing_mmu_tbu3_gdsc {
	reg = <0x18d0a4 0x4>;
	status = "ok";
};

&gpu_cc_cx_gdsc_hw_ctrl {
	reg = <0x3d9953c 0x4>;
};

&gpu_cc_cx_gdsc {
	reg = <0x3d99108 0x4>;
	clocks = <&gcc GCC_GPU_CFG_AHB_CLK>;
	clock-names = "ahb_clk";
	parent-supply = <&VDD_CX_LEVEL>;
	status = "ok";
};

&gpu_cc_gx_domain_addr {
	reg = <0x3d99504 0x4>;
};

&gpu_cc_gx_sw_reset {
	reg = <0x3d99058 0x4>;
};

&gpu_cc_gx_gdsc {
	reg = <0x3d9905c 0x4>;
	clocks = <&gcc GCC_GPU_CFG_AHB_CLK>;
	clock-names = "ahb_clk";
	parent-supply = <&VDD_GX_MXC_VOTER_LEVEL>;
	sw-reset = <&gpu_cc_gx_sw_reset>,
		   <&gpu_cc_gx_acd_reset>,
		   <&gpu_cc_gx_acd_iroot_reset>;
	qcom,skip-disable-before-sw-enable;
	status = "ok";
};

&video_cc_mvs0_gdsc {
	reg = <0xabf809c 0x4>;
	clocks = <&gcc GCC_VIDEO_AHB_CLK>;
	clock-names = "ahb_clk";
	parent-supply = <&VDD_MM_LEVEL>;
	status = "ok";
};

&video_cc_mvs0c_gdsc {
	reg = <0xabf804c 0x4>;
	clocks = <&gcc GCC_VIDEO_AHB_CLK>;
	clock-names = "ahb_clk";
	parent-supply = <&VDD_MM_LEVEL>;
	status = "ok";
};

&video_cc_mvs1_gdsc {
	reg = <0xabf80c0 0x4>;
	clocks = <&gcc GCC_VIDEO_AHB_CLK>;
	clock-names = "ahb_clk";
	parent-supply = <&VDD_MM_LEVEL>;
	status = "ok";
};

&video_cc_mvs1c_gdsc {
	reg = <0xabf8074 0x4>;
	clocks = <&gcc GCC_VIDEO_AHB_CLK>;
	clock-names = "ahb_clk";
	parent-supply = <&VDD_MM_LEVEL>;
	status = "ok";
};

#include "lemans-stub-regulator.dtsi"
#include "lemans-thermal.dtsi"
